# earlgrey register map
Vendor: lowRISC; File version: 0.1
CPU: ibex rev01, little endian, no MPU, no FPU, VTOR, 2 interrupt priority bits, 2 interrupts
Registers are 32-bit, read-write, no defined reset value unless marked. A register's access mark holds for its fields unless they carry their own. Offsets are from the block's base; [hi:lo] are bit positions; {n}, {i} and the like mark numbered series; 'fields as' and 'values as' point back to an identical list.

## SPI_DEVICE — Serial peripheral interface supporting different device modes, suitable for bulk-load of data into and out of the chip
Base 0x40050000
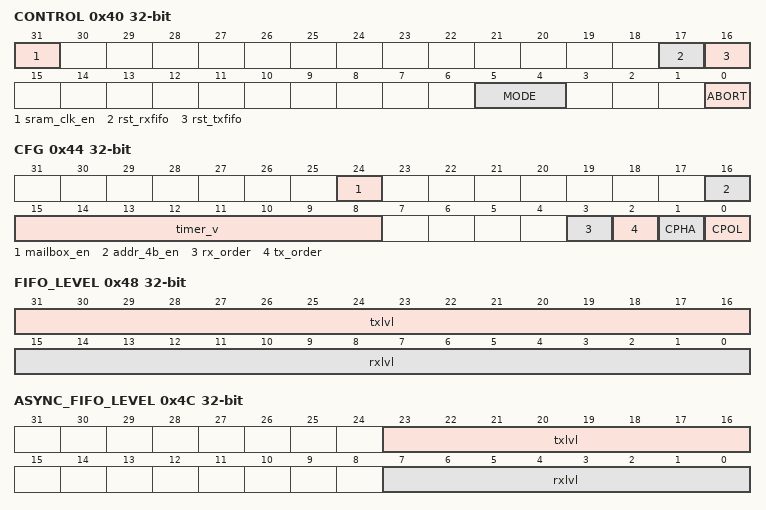
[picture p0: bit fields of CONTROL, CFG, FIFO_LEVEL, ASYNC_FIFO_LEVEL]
0x40 CONTROL
  [31] sram_clk_en — SRAM Clock Enable.This controls the clock gating cell lying on DP SRAM clock. As thenature of absent of SPI_CLK in idle state, the clock mux for SRAMB port cannot be glitch-free MUX. So, it is up to SW to change theclock safely.Programming sequence:1. Check if SPI line is idle2. Clear sram_clk_en to 0.3. Change mode to FwMode for peri clk, FlashMode or PassThrough for SPI_CLK.4. Set sram_clk_en to 1.
  [17] rst_rxfifo — Reset Async RX_FIFO.This only resets asynchronous fifo. If firmware wants to reset SRAMFIFO, it should write 0 into read pointer and write pointer._Note_: This value should be controlled only when SPI interface isin Idle state as this reset signal doesn't have reset synchronizer.
  [16] rst_txfifo — Reset Async TX_FIFO.This only resets asynchronous fifo. If firmware wants to reset SRAMFIFO, it should write 0 into read/write pointers._Note_: This value should be controlled only when SPI interface isin Idle state as this reset signal doesn't have reset synchronizer.
  [5:4] MODE — SPI Device operation mode. Currently only FwMode is supported.
  [0] ABORT — Abort pending TX data in Generic mode.If TX_FIFO (Asynchronous) is full, the TXF waits indefinitely topush the next byte into the asynchronous FIFO. SW may reset theAsync FIFO along with aborting the current task. SW should updatethe write pointer of the TXF in order not to push the byte toAsynchronous FIFO again by TXF logic.
0x44 CFG — Configuration Register
  [24] mailbox_en — Mailbox enable.If 1, in the flash and passthrough mode, the IP checks the incomingaddress and return from the internal Mailbox buffer if the addressfalls into the MAILBOX range(MAILBOX_ADDR:MAILBOX_ADDR+MAILBOX_SIZE)}.
  [16] addr_4b_en — 4B Address Mode enable.This field configures the internal module to receive 32 bits of theSPI commands. The affected commands are the SPI read commandsexcept QPI, and program commands. It is expected for SW toconfigure this field at the configuration stage and leave theupdation to HW until next reset.Even though Read SFDP command has address fields, the SFDP commandis not affected by this field. The command always parse 24 bits onthe SPI line 0 following the SPI command as the address field.
  [15:8] timer_v — number of clocks for RXF to wait.To reduce traffic to SRAM, RXF control module waits given clock cycleif it doesn't fill SRAM data width even if Async RX FIFO is empty.
  [3] rx_order — RX bit order on SDI. Module stores bitstream from MSB to LSB if value is 0.
  [2] tx_order — TX bit order on SDO. 0 for MSB to LSB, 1 for LSB to MSB
  [1] CPHA — Data phase. 0 for negative edge change, 1 for positive edge change
  [0] CPOL — Clock polarity. 0 for normal SPI, 1 for negative edge latch
0x48 FIFO_LEVEL — RX/ TX FIFO levels.
  [31:16] txlvl — TX FIFO level.If TX SRAM FIFO level drops below this value, it triggers interrupt.
  [15:0] rxlvl — RX FIFO level.If RX SRAM FIFO level exceeds this value, it triggers interrupt.
0x4C ASYNC_FIFO_LEVEL ro — RX/ TX Async FIFO levels between main clk and spi clock
  [23:16] txlvl — TX Async FIFO level.This value shows the number of available entry in TX Async FIFO.If the software writes message into SRAM FIFO and update FIFO write pointerbut no clock from the host is given, the data stuck at this async fifo waitinghost toggles SCK. This value represents the number of bytes.
  [7:0] rxlvl — RX Async FIFO level.This value shows the number of available entry in RX Async FIFO.
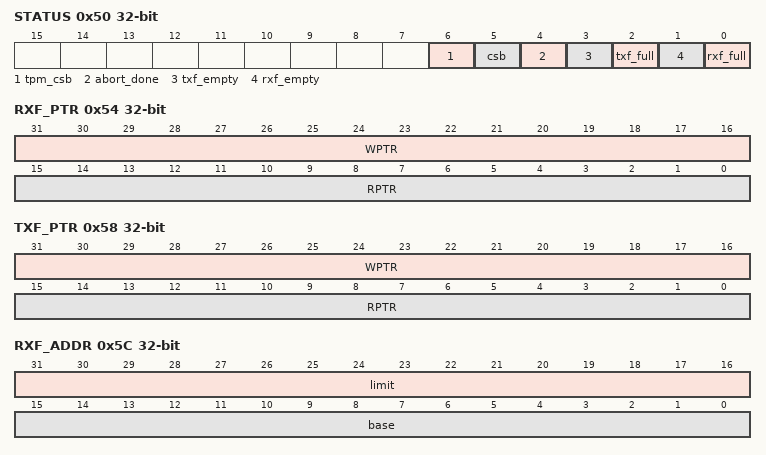
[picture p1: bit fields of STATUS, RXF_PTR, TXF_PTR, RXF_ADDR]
0x50 STATUS ro — SPI Device status register
  [6] tpm_csb — Direct input of TPM CSb
  [5] csb — Direct input of CSb signal
  [4] abort_done — Abort process is completed.Current version does not implement abort_done logic. It is tied to1 always.
  [3] txf_empty — TX FIFO empty
  [2] txf_full — TX FIFO full
  [1] rxf_empty — RX FIFO empty
  [0] rxf_full — RX FIFO full
0x54 RXF_PTR — Receiver FIFO (SRAM) pointers
  [31:16] WPTR — Write pointer. Bit x is phase bit.
  [15:0] RPTR — Read pointer. bit x is for phase bit. check circular fifo description
0x58 TXF_PTR — Transmitter FIFO (SRAM) pointers
  fields as RXF_PTR
0x5C RXF_ADDR — Receiver FIFO (SRAM) Addresses
  [31:16] limit — Limit offset in bytes in the SRAM. Lower 2 bits are ignored.
  [15:0] base — Base offset in bytes in the SRAM. Lower 2 bits are ignored.
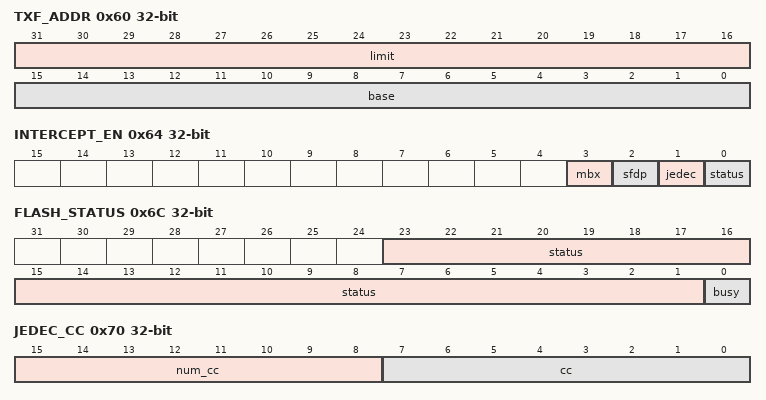
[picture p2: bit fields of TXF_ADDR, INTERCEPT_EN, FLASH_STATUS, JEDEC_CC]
0x60 TXF_ADDR — Transmitter FIFO (SRAM) Addresses
  fields as RXF_ADDR
0x64 INTERCEPT_EN — Intercept Passthrough datapath.
  [3] mbx — If set, Read Command to Mailbox region is processed internally.
  [2] sfdp — If set, Read SFDP is processed internally.
  [1] jedec — If set, Read JEDEC ID is processed internally.
  [0] status — If set, Read Status is processed internally.
0x68 LAST_READ_ADDR ro — Last Read AddressThis register shows the last address accessed by the host system.It is updated by the HW when CSb is de-asserted.
  [31:0] addr — Last address
0x6C FLASH_STATUS — SPI Flash Status register.This register emulates the SPI Flash Status 3, 2, 1 registers.bit [7:0] is for Status register, bit [15:8] is for Status-2 register,and bit [23:16] is for Status-3 register. It is SW responsibility tomaintain this register value up to date.The HW latches the value when SPI Flash transaction begins. Any updatesduring the transaction will be updated after the transaction iscompleted.
  [23:1] status — Rest of the status register.Fields other than the bit 0 (BUSY) and bit 1 (WEL) fields areSW-maintained fields. HW just reads and returns to the host system.Bit 1 (WEL) is a SW modifiable and HW modifiable field. HW updatesthe WEL field when `WRDI` or `WREN` command is received.- [ 1]\: WEL- [ 2]\: BP0- [ 3]\: BP1- [ 4]\: BP2- [ 5]\: TB- [ 6]\: SEC- [ 7]\: SRP0- [ 8]\: SRP1- [ 9]\: QE- [11]\: LB1- [12]\: LB2- [13]\: LB3- [14]\: CMP- [15]\: SUS- [18]\: WPS- [21]\: DRV0- [22]\: DRV1- [23]\: HOLD /RST
  [0] busy — BUSY signal is cleared when CSb is high. SW should readback the register to confirm the value is cleared.
0x70 JEDEC_CC — JEDEC Continuation Code configuration register.Read JEDEC ID must return the continuation code if the manufacturer IDis not shown in the first page of JEDEC table. This register controlsthe Continuation Code.
  [15:8] num_cc — The number that Continuation Code repeats
  [7:0] cc — Continuation Code byte
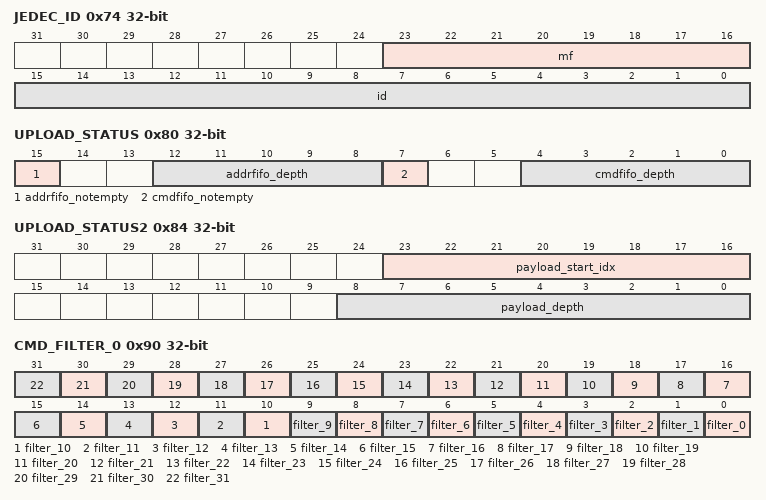
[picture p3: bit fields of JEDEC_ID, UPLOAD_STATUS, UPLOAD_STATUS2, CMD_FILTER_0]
0x74 JEDEC_ID
  [23:16] mf — Manufacturer ID
  [15:0] id — Device ID
0x78 READ_THRESHOLD — Read Buffer threshold register.
  [9:0] threshold — If 0, disable the watermark. If non-zero, when the hostaccess above or equal to the threshold, it reports an interrupt.The value is byte-granularity not SRAM index.
0x7C MAILBOX_ADDR — Mailbox Base address register.The mailbox size is fixed. In this version of IP, the size is 1kB.Lower 10 bits of the Mailbox address is tied to 0.
  [31:0] addr — Mailbox Address. Lower 10 bits are ignored
0x80 UPLOAD_STATUS ro — Upload module status register.
  [15] addrfifo_notempty — Upload Address FIFO Not Empty
  [12:8] addrfifo_depth — Address FIFO Entry
  [7] cmdfifo_notempty — Upload Command FIFO Not Empty
  [4:0] cmdfifo_depth — Command FIFO Entry
0x84 UPLOAD_STATUS2 ro — Upload module status 2 register.This register contains payload related status. payload_depth indicatesthe payload size (from 0 to 256 bytes).payload_start_idx indicates the start of the 256B. This stays 0usually. However, when the SPI host system issues more than 256B ofpayload in a command, this field may not be 0. For example, if thesystem issues 258B payload, the payload_depth is 256 (as the IP onlyholds 256B of payload), the payload_start_idx is 2. SW should read from2 to 255 then 0 and 1.
  [23:16] payload_start_idx — Payload Start Index
  [8:0] payload_depth — Payload buffer depth
0x88 UPLOAD_CMDFIFO ro — Command Fifo Read Port.
  [7:0] data — read data
0x8C UPLOAD_ADDRFIFO ro — Address Fifo Read Port.
  [31:0] data — read data
0x90 CMD_FILTER_0 — Command FilterIf a bit in this CSR is 1, then corresponding SPI command w.r.t thebit position among 256 bit is dropped in SPI Passthrough mode.
  [n] filter_{n} (n=0..31) — If 1, command will be filtered
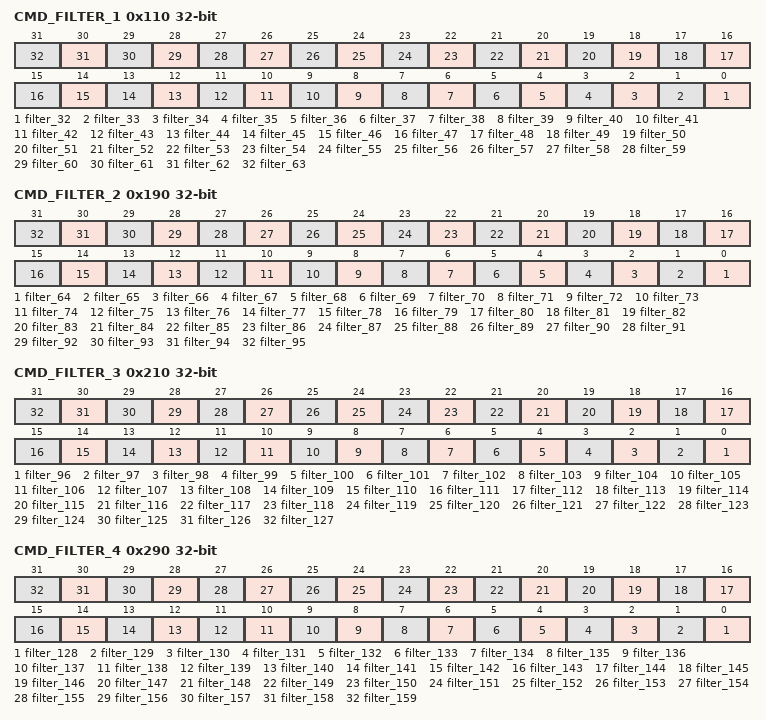
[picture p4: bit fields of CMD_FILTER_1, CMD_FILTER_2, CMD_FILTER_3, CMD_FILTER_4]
0x110 CMD_FILTER_1 — Command FilterIf a bit in this CSR is 1, then corresponding SPI command w.r.t thebit position among 256 bit is dropped in SPI Passthrough mode.
  [n-32] filter_{n} (n=32..63) — If 1, command will be filtered
0x190 CMD_FILTER_2 — Command FilterIf a bit in this CSR is 1, then corresponding SPI command w.r.t thebit position among 256 bit is dropped in SPI Passthrough mode.
  [n-64] filter_{n} (n=64..95) — If 1, command will be filtered
0x210 CMD_FILTER_3 — Command FilterIf a bit in this CSR is 1, then corresponding SPI command w.r.t thebit position among 256 bit is dropped in SPI Passthrough mode.
  [n-96] filter_{n} (n=96..127) — If 1, command will be filtered
0x290 CMD_FILTER_4 — Command FilterIf a bit in this CSR is 1, then corresponding SPI command w.r.t thebit position among 256 bit is dropped in SPI Passthrough mode.
  [n-128] filter_{n} (n=128..159) — If 1, command will be filtered
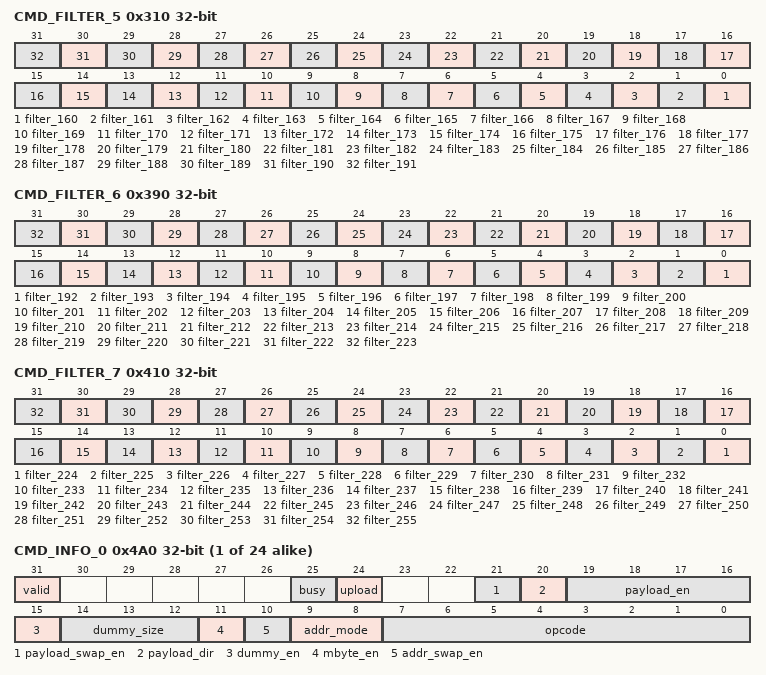
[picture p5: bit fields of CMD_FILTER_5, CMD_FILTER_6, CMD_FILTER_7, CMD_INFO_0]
0x310 CMD_FILTER_5 — Command FilterIf a bit in this CSR is 1, then corresponding SPI command w.r.t thebit position among 256 bit is dropped in SPI Passthrough mode.
  [n-160] filter_{n} (n=160..191) — If 1, command will be filtered
0x390 CMD_FILTER_6 — Command FilterIf a bit in this CSR is 1, then corresponding SPI command w.r.t thebit position among 256 bit is dropped in SPI Passthrough mode.
  [n-192] filter_{n} (n=192..223) — If 1, command will be filtered
0x410 CMD_FILTER_7 — Command FilterIf a bit in this CSR is 1, then corresponding SPI command w.r.t thebit position among 256 bit is dropped in SPI Passthrough mode.
  [n-224] filter_{n} (n=224..255) — If 1, command will be filtered
0x490 ADDR_SWAP_MASK — Address Swap Mask register.This register is used in the SPI passthrough mode. If any of bits inthis register is set, the corresponding address bit in the SPI Readcommands is replaced with the data from !!ADDR_SWAP_DATA.If 3B address mode is active, upper 8bit [31:24] is ignored.
  [31:0] mask — When a bit is 1, the SPI read address to the downstream SPIFlash device is swapped to !!ADDR_SWAP_DATA.
0x494 ADDR_SWAP_DATA — The address value for the address swap feature.
  [31:0] data — Desired value to be swapped for the SPI read commands.
0x498 PAYLOAD_SWAP_MASK — Write Data Swap in the passthrough mode.PAYLOAD_SWAP_MASK CSR provides the SW to change certain bits in thefirst 4 bytes of the write payload in the passthrough mode.
  [31:0] mask — byte mask
0x49C PAYLOAD_SWAP_DATA — Write Data Swap in the passthrough mode.PAYLOAD_SWAP_DATA combined with PAYLOAD_SWAP_MASK provides the SW tochange certain bits in the first 4 bytes of the write payload in thepassthrough mode.The register should be written in Little-Endian order. [7:0] bits areprocessed in the first received payload byte. [31:24] bits for the 4thbyte.
  [31:0] data — replaced data
{0x4A0+4i} CMD_INFO_{i} (i=0..23) — Command Info register.
  [31] valid — Set to 1 if the config in the register is valid
  [25] busy — Set to 1 to set the BUSY bit in the FLASH_STATUS when thecommand is received. This bit is active only when `upload` bit isset.
  [24] upload — Set to 1 to upload the command.If upload field in the command info entry is set, the cmdparseactivates the upload submodule when the opcode is received.`addr_en`, `addr_4B_affected`, and `addr_4b_forced` (TBD) affectthe upload functionality. The three address related configsdefines the command address field size.The logic assumes the following SPI input stream as payload,which max size is 256B. If the command exceeds the maximumpayload size 256B, the logic wraps the payload and overwrites.
  [21] payload_swap_en — Swap the first byte of the write payload.If `payload_swap_en` is set, the passthrough logic swaps the first byte of the write payload with DATA_SWAP CSR.`payload_swap_en` only works with write data and SingleIO mode. `payload_en` must be 4'b 0001 and `paylod_dir` to be PayloadIn.
  [20] payload_dir — Set to 1 if the command returns data. If 0, the payloadsends to the downstream Flash device.
  [19:16] payload_en — Payload Enable per SPI lane.Set to non-zero if the command has payload at the end of theprotocol. This field has four bits. Each bit represents the SPIline. If a command is a Single IO command and returns data to thehost system, the data is returned on the MISO line (IO[1]). Inthis case, SW sets payload_en to 4'b 0010.
  [15] dummy_en — Set to 1 if the command has a dummy cycle following the address field.
  [14:12] dummy_size — The number of dummy cycles -1 for the command
  [11] mbyte_en — If 1, the command has a MByte field following theaddress field. This is set to 1 for DualIO, QuadIO commands.
  [10] addr_swap_en — This field is used in the passthrough logic.If this field is set to 1, the address in the passthrough commandis replaced to the preconfigured value.
  [9:8] addr_mode — Command address modeA command can have four modes:- 0: Command does not have an address field- 1: CFG.addr_4b_en decides the address size (3B/4B)- 2: Address size is always 3B regardless of CFG.addr_4b_en- 3: Address size is always 4B regardless of CFG.addr_4b_en
  [7:0] opcode — Command Opcode
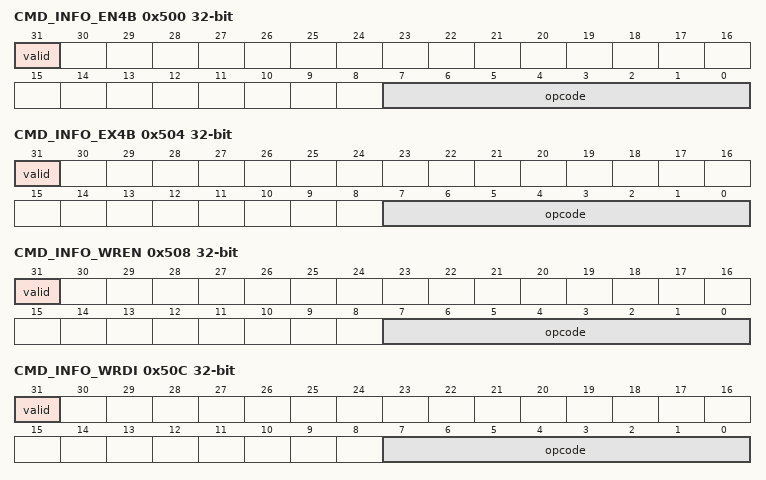
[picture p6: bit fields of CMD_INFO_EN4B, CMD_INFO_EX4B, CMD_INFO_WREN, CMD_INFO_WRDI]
0x500 CMD_INFO_EN4B — Opcode for EN4B.If the register is active, it affects in flash / passthrough modes.
  [31] valid — If 1, Opcode affects
  [7:0] opcode — EN4B opcode
0x504 CMD_INFO_EX4B — Opcode for EX4B
  [31] valid — If 1, Opcode affects
  [7:0] opcode — EX4B opcode
0x508 CMD_INFO_WREN — Opcode for Write Enable (WREN)
  [31] valid — If 1, opcode affects
  [7:0] opcode — WREN opcode
0x50C CMD_INFO_WRDI — Opcode for Write Disable (WRDI)
  [31] valid — If 1, opcode affects
  [7:0] opcode — WRDI opcode
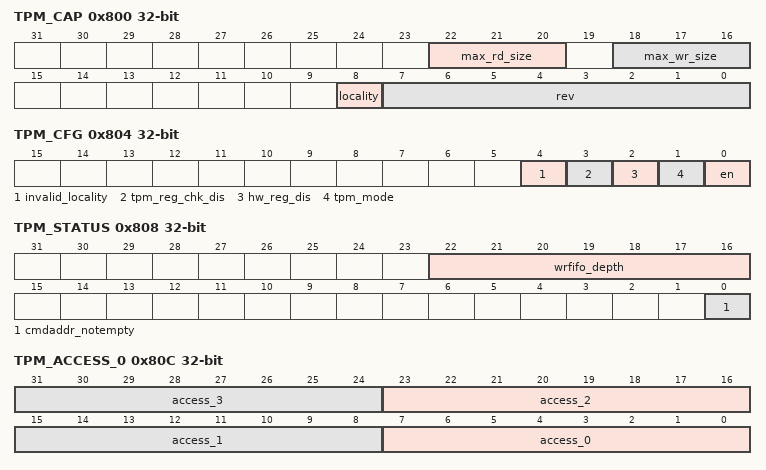
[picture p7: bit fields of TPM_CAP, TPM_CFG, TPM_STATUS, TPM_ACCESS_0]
0x800 TPM_CAP ro — TPM HWIP Capability register.This register shows the features the current TPM HWIP supports.
  [22:20] max_rd_size — The maximum read size in bytes the TPM submodule supports.The value is the exponent of the 2.- 3'b 010: Support up to 4B- 3'b 011: Support up to 8B- 3'b 100: Support up to 16B- 3'b 101: Support up to 32B- 3'b 110: Support up to 64BAll other values are reserved.It is not recommended for SW to advertise TPM supporting more than `max_rd_size` to the South Bridge.
  [18:16] max_wr_size — The maximum write size in bytes the TPM submodule supports.The value is the exponent of the 2.- 3'b 010: Support up to 4B- 3'b 011: Support up to 8B- 3'b 100: Support up to 16B- 3'b 101: Support up to 32B- 3'b 110: Support up to 64BAll other values are reserved.It is not recommended for SW to advertise TPM supporting more than `max_wr_size` to the South Bridge.
  [8] locality — If 1, the TPM submodule supports 5 Locality.If 0, only one Locality is provided
  [7:0] rev — Revision of the TPM submodule
0x804 TPM_CFG — TPM Configuration register.
  [4] invalid_locality — If 1, TPM submodule returns the invalid data (0xFF) for theout of the max Locality request.If it is a write request, HW still uploads the command and address.SW needs to process the incoming invalid command.If 0, TPM submodule uploads the TPM command and address. The SW maywrite 0xFF to the read FIFO.Note: The TPM submodule uploads the TPM commands that do not fallinto the FIFO registers (0xD4_XXXX) regardless of`invalid_locality` bit.
  [3] tpm_reg_chk_dis — If 1, the logic does not compare the upper 8 bit of thereceived address with the TpmAddr constant, D4h.If this field is 0, the HW uploads the command, address, and writepayload to the buffers in case of address that is not 0xD4_XXXX.
  [2] hw_reg_dis — If 0, TPM submodule directly returns the return-by-HW registers for the read requests.If 1, TPM submodule uploads the TPM command regardless of the address, and the SW may return the value through the read FIFO.
  [1] tpm_mode — Configure the TPM mode. 1 for CRB, 0 for FIFO.If the SW set this field to 1, the HW logic always pushes thecommand/addr and write data to buffers. The logic does not comparethe incoming address to the list of managed-by-HW registeraddresses.The invalid locality check still runs based on the invalid_localityconfiguration.
  [0] en — If 1, TPM submodule accepts the transactions over SPI
0x808 TPM_STATUS ro — TPM submodule state register.The TPM_STATUS CSR provides the current TPM status, mostly the buffer and FIFO status.
  [22:16] wrfifo_depth — This field represents the current write FIFO depth.
  [0] cmdaddr_notempty — If 1, the TPM_CMD_ADDR has a valid data. This status is reported via the interrupt also.
0x80C TPM_ACCESS_0 — TPM_ACCESS_x register.
  [8n+7:8n] access_{n} (n=0..3) — TPM_ACCESS
0x81C TPM_ACCESS_1 — TPM_ACCESS_x register.
  [7:0] access_4 — TPM_ACCESS
0x820 TPM_STS — TPM_STS_x register.The register is mirrored to all Localities.The value is returned to the host system only when the activeLocalityin the TPM_ACCESS_x is matched to the current received Locality.
  [31:0] sts — TPM_STS_x
0x824 TPM_INTF_CAPABILITY
  [31:0] intf_capability
0x828 TPM_INT_ENABLE
  [31:0] int_enable
0x82C TPM_INT_VECTOR
  [7:0] int_vector
0x830 TPM_INT_STATUS
  [31:0] int_status
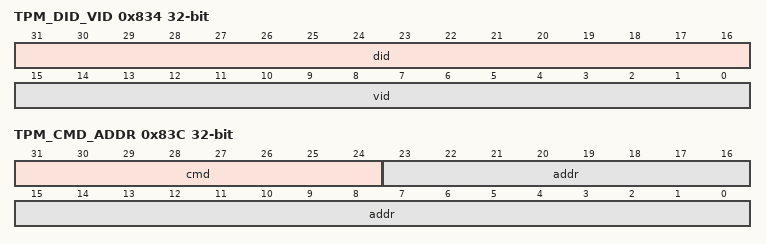
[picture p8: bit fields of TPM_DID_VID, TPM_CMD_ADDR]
0x834 TPM_DID_VID — TPM_DID/ TPM_VID register
  [31:16] did — TPM_DID
  [15:0] vid — TPM_VID
0x838 TPM_RID
  [7:0] rid
0x83C TPM_CMD_ADDR ro — TPM Command and Address bufferThe SW may get the received TPM command and address by readin gthis CSR.
  [31:24] cmd — received command
  [23:0] addr — received address
0x840 TPM_READ_FIFO wo — TPM Read command return data FIFO.The write port of the read command FIFO.
  [31:0] value — write port of the read FIFO
0x844 TPM_WRITE_FIFO ro — TPM Write command received data FIFO.
  [7:0] value — Read only port of the write FIFO
